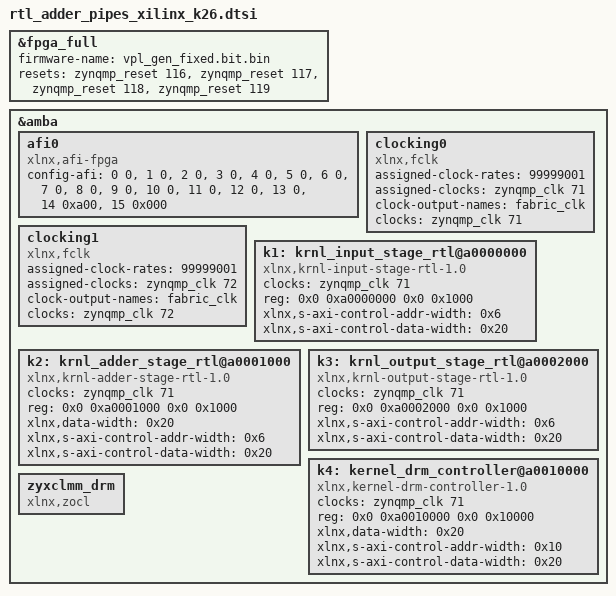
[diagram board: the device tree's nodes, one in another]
/*
 * CAUTION: This file is automatically generated by Xilinx.
 * Version: XSCT 2022.1
 * Today is: Tue Jan 31 11:31:57 2023
 */


/dts-v1/;
/plugin/;
/ {
	fragment@0 {
		target = <&fpga_full>;
		overlay0: __overlay__ {
			#address-cells = <2>;
			#size-cells = <2>;
			firmware-name = "vpl_gen_fixed.bit.bin";
			resets = <&zynqmp_reset 116>, <&zynqmp_reset 117>, <&zynqmp_reset 118>, <&zynqmp_reset 119>;
		};
	};
	fragment@1 {
		target = <&amba>;
		overlay1: __overlay__ {
			afi0: afi0 {
				compatible = "xlnx,afi-fpga";
				config-afi = < 0 0>, <1 0>, <2 0>, <3 0>, <4 0>, <5 0>, <6 0>, <7 0>, <8 0>, <9 0>, <10 0>, <11 0>, <12 0>, <13 0>, <14 0xa00>, <15 0x000>;
			};
			clocking0: clocking0 {
				#clock-cells = <0>;
				assigned-clock-rates = <99999001>;
				assigned-clocks = <&zynqmp_clk 71>;
				clock-output-names = "fabric_clk";
				clocks = <&zynqmp_clk 71>;
				compatible = "xlnx,fclk";
			};
			clocking1: clocking1 {
				#clock-cells = <0>;
				assigned-clock-rates = <99999001>;
				assigned-clocks = <&zynqmp_clk 72>;
				clock-output-names = "fabric_clk";
				clocks = <&zynqmp_clk 72>;
				compatible = "xlnx,fclk";
			};
		};
	};
	fragment@2 {
		target = <&amba>;
		overlay2: __overlay__ {
			#address-cells = <2>;
			#size-cells = <2>;
			k1: krnl_input_stage_rtl@a0000000 {
				/* This is a place holder node for a custom IP, user may need to update the entries */
				clock-names = "ap_clk";
				clocks = <&zynqmp_clk 71>;
				compatible = "xlnx,krnl-input-stage-rtl-1.0";
				reg = <0x0 0xa0000000 0x0 0x1000>;
				xlnx,s-axi-control-addr-width = <0x6>;
				xlnx,s-axi-control-data-width = <0x20>;
			};
			k2: krnl_adder_stage_rtl@a0001000 {
				/* This is a place holder node for a custom IP, user may need to update the entries */
				clock-names = "ap_clk";
				clocks = <&zynqmp_clk 71>;
				compatible = "xlnx,krnl-adder-stage-rtl-1.0";
				reg = <0x0 0xa0001000 0x0 0x1000>;
				xlnx,data-width = <0x20>;
				xlnx,s-axi-control-addr-width = <0x6>;
				xlnx,s-axi-control-data-width = <0x20>;
			};
			k3: krnl_output_stage_rtl@a0002000 {
				/* This is a place holder node for a custom IP, user may need to update the entries */
				clock-names = "ap_clk";
				clocks = <&zynqmp_clk 71>;
				compatible = "xlnx,krnl-output-stage-rtl-1.0";
				reg = <0x0 0xa0002000 0x0 0x1000>;
				xlnx,s-axi-control-addr-width = <0x6>;
				xlnx,s-axi-control-data-width = <0x20>;
			};
			k4: kernel_drm_controller@a0010000 {
				/* This is a place holder node for a custom IP, user may need to update the entries */
				clock-names = "ap_clk";
				clocks = <&zynqmp_clk 71>;
				compatible = "xlnx,kernel-drm-controller-1.0";
				reg = <0x0 0xa0010000 0x0 0x10000>;
				xlnx,data-width = <0x20>;
				xlnx,s-axi-control-addr-width = <0x10>;
				xlnx,s-axi-control-data-width = <0x20>;
			};
			zyxclmm_drm {
				compatible = "xlnx,zocl";
			};
		};
	};
};
